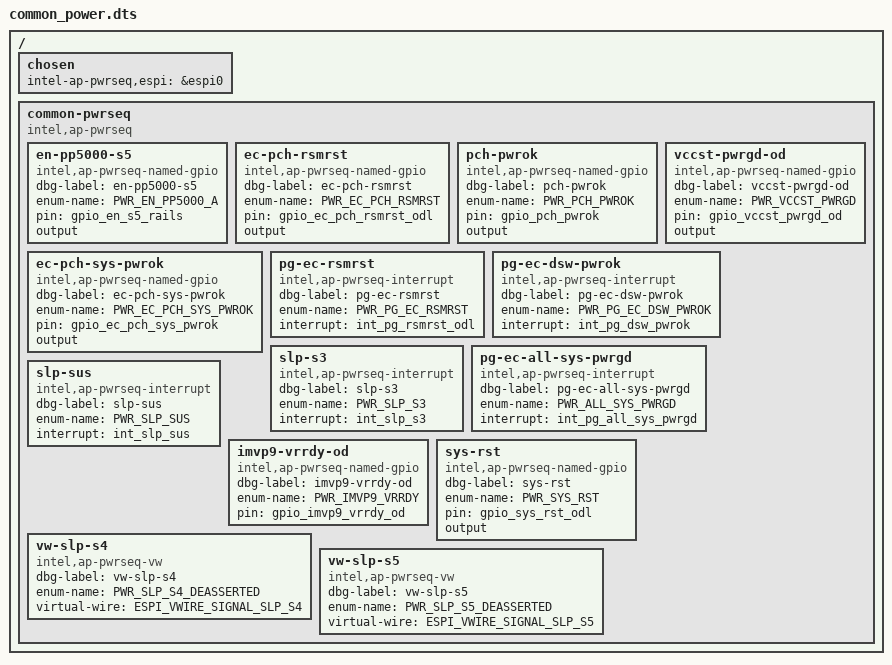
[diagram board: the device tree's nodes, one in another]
/* Copyright 2022 The Chromium OS Authors. All rights reserved.
 * Use of this source code is governed by a BSD-style license that can be
 * found in the LICENSE file.
 */

/ {
	chosen {
		intel-ap-pwrseq,espi = &espi0;
	};

	common-pwrseq {
		compatible = "intel,ap-pwrseq";

		en-pp5000-s5 {
			compatible = "intel,ap-pwrseq-named-gpio";
			dbg-label = "en-pp5000-s5";
			enum-name = "PWR_EN_PP5000_A";
			pin = <&gpio_en_s5_rails>;
			output;
		};
		ec-pch-rsmrst {
			compatible = "intel,ap-pwrseq-named-gpio";
			dbg-label = "ec-pch-rsmrst";
			enum-name = "PWR_EC_PCH_RSMRST";
			pin = <&gpio_ec_pch_rsmrst_odl>;
			output;
		};
		pch-pwrok {
			compatible = "intel,ap-pwrseq-named-gpio";
			dbg-label = "pch-pwrok";
			enum-name = "PWR_PCH_PWROK";
			pin = <&gpio_pch_pwrok>;
			output;
		};
		ec-pch-sys-pwrok {
			compatible = "intel,ap-pwrseq-named-gpio";
			dbg-label = "ec-pch-sys-pwrok";
			enum-name = "PWR_EC_PCH_SYS_PWROK";
			pin = <&gpio_ec_pch_sys_pwrok>;
			output;
		};
		vccst-pwrgd-od {
			compatible = "intel,ap-pwrseq-named-gpio";
			dbg-label = "vccst-pwrgd-od";
			enum-name = "PWR_VCCST_PWRGD";
			pin = <&gpio_vccst_pwrgd_od>;
			output;
		};
		pg-ec-rsmrst {
			compatible = "intel,ap-pwrseq-interrupt";
			dbg-label = "pg-ec-rsmrst";
			enum-name = "PWR_PG_EC_RSMRST";
			interrupt = <&int_pg_rsmrst_odl>;
		};
		pg-ec-dsw-pwrok {
			compatible = "intel,ap-pwrseq-interrupt";
			dbg-label = "pg-ec-dsw-pwrok";
			enum-name = "PWR_PG_EC_DSW_PWROK";
			interrupt = <&int_pg_dsw_pwrok>;
		};
		slp-s3 {
			compatible = "intel,ap-pwrseq-interrupt";
			dbg-label = "slp-s3";
			enum-name = "PWR_SLP_S3";
			interrupt = <&int_slp_s3>;
		};
		pg-ec-all-sys-pwrgd {
			compatible = "intel,ap-pwrseq-interrupt";
			dbg-label = "pg-ec-all-sys-pwrgd";
			enum-name = "PWR_ALL_SYS_PWRGD";
			interrupt = <&int_pg_all_sys_pwrgd>;
		};
		slp-sus {
			compatible = "intel,ap-pwrseq-interrupt";
			dbg-label = "slp-sus";
			enum-name = "PWR_SLP_SUS";
			interrupt = <&int_slp_sus>;
		};
		imvp9-vrrdy-od {
			compatible = "intel,ap-pwrseq-named-gpio";
			dbg-label = "imvp9-vrrdy-od";
			enum-name = "PWR_IMVP9_VRRDY";
			pin = <&gpio_imvp9_vrrdy_od>;
		};
		sys-rst {
			compatible = "intel,ap-pwrseq-named-gpio";
			dbg-label = "sys-rst";
			enum-name = "PWR_SYS_RST";
			pin = <&gpio_sys_rst_odl>;
			output;
		};
		vw-slp-s4 {
			compatible = "intel,ap-pwrseq-vw";
			dbg-label = "vw-slp-s4";
			enum-name = "PWR_SLP_S4_DEASSERTED";
			virtual-wire = "ESPI_VWIRE_SIGNAL_SLP_S4";
		};
		vw-slp-s5 {
			compatible = "intel,ap-pwrseq-vw";
			dbg-label = "vw-slp-s5";
			enum-name = "PWR_SLP_S5_DEASSERTED";
			virtual-wire = "ESPI_VWIRE_SIGNAL_SLP_S5";
		};
	};
};
